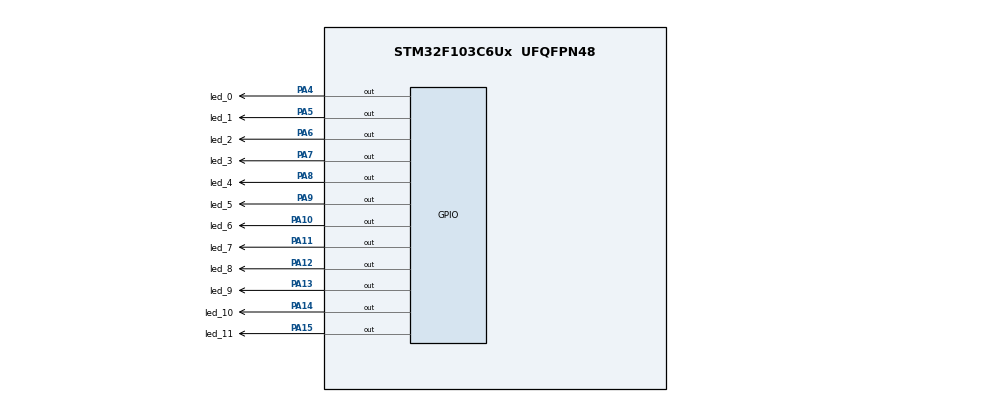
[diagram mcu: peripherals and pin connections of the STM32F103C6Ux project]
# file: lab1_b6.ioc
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Mcu.Family=STM32F1
Mcu.Name=STM32F103C6Ux
Mcu.Package=UFQFPN48
NVIC.PriorityGroup=NVIC_PRIORITYGROUP_4
PA10.GPIO_Label=led_6
PA10.Signal=GPIO_Output
PA11.GPIO_Label=led_7
PA11.Signal=GPIO_Output
PA12.GPIO_Label=led_8
PA12.Signal=GPIO_Output
PA13.GPIO_Label=led_9
PA13.Signal=GPIO_Output
PA14.GPIO_Label=led_10
PA14.Signal=GPIO_Output
PA15.GPIO_Label=led_11
PA15.Signal=GPIO_Output
PA4.GPIO_Label=led_0
PA4.Signal=GPIO_Output
PA5.GPIO_Label=led_1
PA5.Signal=GPIO_Output
PA6.GPIO_Label=led_2
PA6.Signal=GPIO_Output
PA7.GPIO_Label=led_3
PA7.Signal=GPIO_Output
PA8.GPIO_Label=led_4
PA8.Signal=GPIO_Output
PA9.GPIO_Label=led_5
PA9.Signal=GPIO_Output
ProjectManager.HeapSize=0x200
ProjectManager.StackSize=0x400
ProjectManager.TargetToolchain=STM32CubeIDE
RCC.APB1Freq_Value=8000000
RCC.APB2Freq_Value=8000000
VP_SYS_VS_ND.Mode=No_Debug
board=custom

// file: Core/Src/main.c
/* USER CODE BEGIN Header */
/**
  ******************************************************************************
  * @file           : main.c
  * @brief          : Main program body
  ******************************************************************************
  * @attention
  *
  * <h2><center>&copy; Copyright (c) 2022 STMicroelectronics.
  * All rights reserved.</center></h2>
  *
  * This software component is licensed by ST under BSD 3-Clause license,
  * the "License"; You may not use this file except in compliance with the
  * License. You may obtain a copy of the License at:
  *                        opensource.org/licenses/BSD-3-Clause
  *
  ******************************************************************************
  */
/* USER CODE END Header */
#include "main.h"

void SystemClock_Config(void);
static void MX_GPIO_Init(void);

void  clearAllClock(){
  HAL_GPIO_WritePin(led_0_GPIO_Port,led_0_Pin,1);
  HAL_GPIO_WritePin(led_1_GPIO_Port,led_1_Pin,1);
  HAL_GPIO_WritePin(led_2_GPIO_Port,led_2_Pin,1);
  HAL_GPIO_WritePin(led_3_GPIO_Port,led_3_Pin,1);
  HAL_GPIO_WritePin(led_4_GPIO_Port,led_4_Pin,1);
  HAL_GPIO_WritePin(led_5_GPIO_Port,led_5_Pin,1);
  HAL_GPIO_WritePin(led_6_GPIO_Port,led_6_Pin,1);
  HAL_GPIO_WritePin(led_7_GPIO_Port,led_7_Pin,1);
  HAL_GPIO_WritePin(led_8_GPIO_Port,led_8_Pin,1);
  HAL_GPIO_WritePin(led_9_GPIO_Port,led_9_Pin,1);
  HAL_GPIO_WritePin(led_10_GPIO_Port,led_10_Pin,1);
  HAL_GPIO_WritePin(led_11_GPIO_Port,led_11_Pin,1);
}
void setNumberOnClock(int num){
  switch(num){
    case 0:HAL_GPIO_WritePin(led_0_GPIO_Port,led_0_Pin,0);break;
    case 1:HAL_GPIO_WritePin(led_1_GPIO_Port,led_1_Pin,0);break;
    case 2:HAL_GPIO_WritePin(led_2_GPIO_Port,led_2_Pin,0);break;
    case 3:HAL_GPIO_WritePin(led_3_GPIO_Port,led_3_Pin,0);break;
    case 4:HAL_GPIO_WritePin(led_4_GPIO_Port,led_4_Pin,0);break;
    case 5:HAL_GPIO_WritePin(led_5_GPIO_Port,led_5_Pin,0);break;
    case 6:HAL_GPIO_WritePin(led_6_GPIO_Port,led_6_Pin,0);break;
    case 7:HAL_GPIO_WritePin(led_7_GPIO_Port,led_7_Pin,0);break;
    case 8:HAL_GPIO_WritePin(led_8_GPIO_Port,led_8_Pin,0);break;
    case 9:HAL_GPIO_WritePin(led_9_GPIO_Port,led_9_Pin,0);break;
    case 10:HAL_GPIO_WritePin(led_10_GPIO_Port,led_10_Pin,0);break;
    case 11:HAL_GPIO_WritePin(led_11_GPIO_Port,led_11_Pin,0);break;
    default: break;
  }
}
void clearNumberOnClock(int num){
  switch(num){
    case 0:HAL_GPIO_WritePin(led_0_GPIO_Port,led_0_Pin,1);break;
    case 1:HAL_GPIO_WritePin(led_1_GPIO_Port,led_1_Pin,1);break;
    case 2:HAL_GPIO_WritePin(led_2_GPIO_Port,led_2_Pin,1);break;
    case 3:HAL_GPIO_WritePin(led_3_GPIO_Port,led_3_Pin,1);break;
    case 4:HAL_GPIO_WritePin(led_4_GPIO_Port,led_4_Pin,1);break;
    case 5:HAL_GPIO_WritePin(led_5_GPIO_Port,led_5_Pin,1);break;
    case 6:HAL_GPIO_WritePin(led_6_GPIO_Port,led_6_Pin,1);break;
    case 7:HAL_GPIO_WritePin(led_7_GPIO_Port,led_7_Pin,1);break;
    case 8:HAL_GPIO_WritePin(led_8_GPIO_Port,led_8_Pin,1);break;
    case 9:HAL_GPIO_WritePin(led_9_GPIO_Port,led_9_Pin,1);break;
    case 10:HAL_GPIO_WritePin(led_10_GPIO_Port,led_10_Pin,1);break;
    case 11:HAL_GPIO_WritePin(led_11_GPIO_Port,led_11_Pin,1);break;
    default: break;
  }
}
int main(void)
{

  /* MCU Configuration--------------------------------------------------------*/

  /* Reset of all peripherals, Initializes the Flash interface and the Systick. */
  HAL_Init();

  /* Configure the system clock */
  SystemClock_Config();

  /* Initialize all configured peripherals */
  MX_GPIO_Init();

  /* Infinite loop */
  /* USER CODE BEGIN WHILE */
  int exercise=8;
  int8_t hour=11;
  int8_t minute=54;
  int8_t second=0;
  int8_t i=0;
  while (1)
  {
    /* USER CODE END WHILE */
    switch(exercise){
      case 6:
        if(i<12){
          clearAllClock();
          setNumberOnClock(i++);
        }
        else i=0;
        break;
      case 8:
    clearAllClock();
    setNumberOnClock((int)(second/5));
    setNumberOnClock((int)(minute/5));
    setNumberOnClock((int)(hour));
    if(second<59){
      second++;
    }
    else{
      if(minute<59){
        minute++;
      }
      else{
        if(hour<11){
          hour++;
        }
        else{
          hour=0;
        }
        minute=0;
      }
      second=0;
    }
    break;
    }
    HAL_Delay(20);
  }
}

void SystemClock_Config(void)
{
  RCC_OscInitTypeDef RCC_OscInitStruct = {0};
  RCC_ClkInitTypeDef RCC_ClkInitStruct = {0};

  /** Initializes the RCC Oscillators according to the specified parameters
  * in the RCC_OscInitTypeDef structure.
  */
  RCC_OscInitStruct.OscillatorType = RCC_OSCILLATORTYPE_HSI;
  RCC_OscInitStruct.HSIState = RCC_HSI_ON;
  RCC_OscInitStruct.HSICalibrationValue = RCC_HSICALIBRATION_DEFAULT;
  RCC_OscInitStruct.PLL.PLLState = RCC_PLL_NONE;
  if (HAL_RCC_OscConfig(&RCC_OscInitStruct) != HAL_OK)
  {
    Error_Handler();
  }
  /** Initializes the CPU, AHB and APB buses clocks
  */
  RCC_ClkInitStruct.ClockType = RCC_CLOCKTYPE_HCLK|RCC_CLOCKTYPE_SYSCLK
                              |RCC_CLOCKTYPE_PCLK1|RCC_CLOCKTYPE_PCLK2;
  RCC_ClkInitStruct.SYSCLKSource = RCC_SYSCLKSOURCE_HSI;
  RCC_ClkInitStruct.AHBCLKDivider = RCC_SYSCLK_DIV1;
  RCC_ClkInitStruct.APB1CLKDivider = RCC_HCLK_DIV1;
  RCC_ClkInitStruct.APB2CLKDivider = RCC_HCLK_DIV1;

  if (HAL_RCC_ClockConfig(&RCC_ClkInitStruct, FLASH_LATENCY_0) != HAL_OK)
  {
    Error_Handler();
  }
}

static void MX_GPIO_Init(void)
{
  GPIO_InitTypeDef GPIO_InitStruct = {0};

  /* GPIO Ports Clock Enable */
  __HAL_RCC_GPIOA_CLK_ENABLE();

  /*Configure GPIO pin Output Level */
  HAL_GPIO_WritePin(GPIOA, led_0_Pin|led_1_Pin|led_2_Pin|led_3_Pin
                          |led_4_Pin|led_5_Pin|led_6_Pin|led_7_Pin
                          |led_8_Pin|led_9_Pin|led_10_Pin|led_11_Pin, GPIO_PIN_RESET);

  /*Configure GPIO pins : led_0_Pin led_1_Pin led_2_Pin led_3_Pin
                           led_4_Pin led_5_Pin led_6_Pin led_7_Pin
                           led_8_Pin led_9_Pin led_10_Pin led_11_Pin */
  GPIO_InitStruct.Pin = led_0_Pin|led_1_Pin|led_2_Pin|led_3_Pin
                          |led_4_Pin|led_5_Pin|led_6_Pin|led_7_Pin
                          |led_8_Pin|led_9_Pin|led_10_Pin|led_11_Pin;
  GPIO_InitStruct.Mode = GPIO_MODE_OUTPUT_PP;
  GPIO_InitStruct.Pull = GPIO_NOPULL;
  GPIO_InitStruct.Speed = GPIO_SPEED_FREQ_LOW;
  HAL_GPIO_Init(GPIOA, &GPIO_InitStruct);

}

void Error_Handler(void)
{
  __disable_irq();
  while (1)
  {
  }
}

/************************ (C) COPYRIGHT STMicroelectronics *****END OF FILE****/
